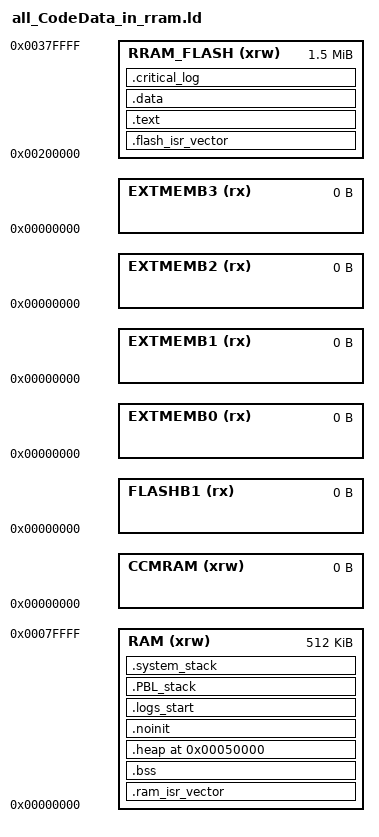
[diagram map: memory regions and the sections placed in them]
/*
 * This file is part of the µOS++ distribution.
 *   (https://github.com/micro-os-plus)
 * Copyright (c) 2014 Liviu Ionescu.
 *
 * Permission is hereby granted, free of charge, to any person
 * obtaining a copy of this software and associated documentation
 * files (the "Software"), to deal in the Software without
 * restriction, including without limitation the rights to use,
 * copy, modify, merge, publish, distribute, sublicense, and/or
 * sell copies of the Software, and to permit persons to whom
 * the Software is furnished to do so, subject to the following
 * conditions:
 *
 * The above copyright notice and this permission notice shall be
 * included in all copies or substantial portions of the Software.
 *
 * THE SOFTWARE IS PROVIDED "AS IS", WITHOUT WARRANTY OF ANY KIND,
 * EXPRESS OR IMPLIED, INCLUDING BUT NOT LIMITED TO THE WARRANTIES
 * OF MERCHANTABILITY, FITNESS FOR A PARTICULAR PURPOSE AND
 * NONINFRINGEMENT. IN NO EVENT SHALL THE AUTHORS OR COPYRIGHT
 * HOLDERS BE LIABLE FOR ANY CLAIM, DAMAGES OR OTHER LIABILITY,
 * WHETHER IN AN ACTION OF CONTRACT, TORT OR OTHERWISE, ARISING
 * FROM, OUT OF OR IN CONNECTION WITH THE SOFTWARE OR THE USE OR
 * OTHER DEALINGS IN THE SOFTWARE.
 */

/* Default linker script for Cortex-M  */
 
 /**************Linker Script for Performance Testing**********************************
 * All code and data will be executing from RRAM.
 * RAM ISR, BSS, stack and heap are in RAM.
 *************************************************************************************/
 
 
 MEMORY
{
  RRAM_FLASH (xrw) : ORIGIN = 0x00200000, LENGTH = 0x00180000
  RAM (xrw) : ORIGIN = 0x00000000, LENGTH = 0x00080000

  /*
   * Optional sections; define the origin and length to match
   * the the specific requirements of your hardware. The zero
   * length prevents inadvertent allocation.
   */
  CCMRAM (xrw) : ORIGIN = 0x00000000, LENGTH = 0
  FLASHB1 (rx) : ORIGIN = 0x00000000, LENGTH = 0
  EXTMEMB0 (rx) : ORIGIN = 0x00000000, LENGTH = 0
  EXTMEMB1 (rx) : ORIGIN = 0x00000000, LENGTH = 0
  EXTMEMB2 (rx) : ORIGIN = 0x00000000, LENGTH = 0
  EXTMEMB3 (rx) : ORIGIN = 0x00000000, LENGTH = 0
}
 
 _ln_PBL_stack__ = ORIGIN(RAM) + LENGTH(RAM);
 _ln_PBL_stack_size__ = 0x200 ;
 _ln_PBL_stack_limit__ = _ln_PBL_stack__ - _ln_PBL_stack_size__ ; 

/*
 * The '__stack' definition is required by crt0, do not remove it.
 */
__stack = _ln_PBL_stack_limit__ ;

_estack = __stack; 	/* End of System Stack */

/*
 * Default stack sizes.
 * These are used by the startup in order to allocate stacks 
 * for the different modes.
 */

__Main_Stack_Size = 10240 ;		/* 10 KB system stack */

PROVIDE ( _Main_Stack_Size = __Main_Stack_Size ) ;

__Main_Stack_Limit = __stack  - __Main_Stack_Size ;

/* "PROVIDE" allows to easily override these values from an 
 * object file or the command line. */
PROVIDE ( _Main_Stack_Limit = __Main_Stack_Limit ) ;

/*
 * Default heap definitions.
 * The heap start immediately after the last statically allocated 
 * .sbss/.noinit section, and extends up to the main stack limit.
 */
PROVIDE ( _Heap_Begin = _end_noinit ) ;
PROVIDE ( _Heap_Limit = __stack - __Main_Stack_Size ) ;
/* 
 * The entry point is informative, for debuggers and simulators,
 * since the Cortex-M vector points to it anyway.
 */
ENTRY(_start)


/* Sections Definitions */

SECTIONS
{
    /*
     * For Cortex-M devices, the beginning of the startup code is stored in
     * the .flash_isr_vector section, which goes to RRAM(FLASH). 
     */
    .flash_isr_vector : ALIGN(4)
    {
        FILL(0xFF)
        
        _ln_RF_flash_isr_vector_start__ = . ;
        __vectors_start = ABSOLUTE(.) ;
        
        KEEP(*(.flash_isr_vector))     	/* Interrupt vectors */
        
		KEEP(*(.cfmconfig))			/*Freescale configuration words */   	     
    } >RRAM_FLASH
    
 	_ln_start_add_ram_isr_vector = _ln_RF_flash_isr_vector_start__ + SIZEOF(.flash_isr_vector) ;
    
    .ram_isr_vector : ALIGN(4)         /* which goes to RAM*/
    {
    	FILL(0xFF)
    	_ln_addr_map_to_ram = ABSOLUTE(.); /*starting address of ram*/
    	KEEP(*(.ram_isr_vector))
    	. += 56;                        /* 64 bytes allocated for ram vector*/
    	. = ALIGN(4) ; 
    	
    } >RAM
    
    _ln_ram_isr_vector_size = SIZEOF(.ram_isr_vector);
    
	/*
     * The program code is stored in the .text section, 
     * which goes to FLASH.
     */
    .text : ALIGN(4)
    {
        *(.after_vectors .after_vectors.*)	/* Startup code and ISR */
        *(.text .text.*)			/* all remaining code */

 		/* read-only data (constants) */
        *(.rodata .rodata.* .constdata .constdata.*) 		

        *(vtable)					/* C++ virtual tables */

		KEEP(*(.eh_frame*))

		/*
		 * Stub sections generated by the linker, to glue together 
		 * ARM and Thumb code. .glue_7 is used for ARM code calling 
		 * Thumb code, and .glue_7t is used for Thumb code calling 
		 * ARM code. Apparently always generated by the linker, for some
		 * architectures, so better leave them here.
		 */
        *(.glue_7)
        *(.glue_7t)

    } >RRAM_FLASH

    /*
     * The initialised data section.
     *
     * The program executes knowing that the data is in the RAM
     * but the loader puts the initial values in the FLASH (inidata).
     * It is one task of the startup to copy the initial values from 
     * FLASH to RAM.
     */
    .data : ALIGN(4)
    {
    	FILL(0xFF)
        /* This is used by the startup code to initialise the .data section */
        
        __data_start__ = . ;
		*(.data_begin .data_begin.*)

		*(.data .data.*)
		
		*(.data_end .data_end.*)
	    . = ALIGN(4);

	    /* This is used by the startup code to initialise the .data section */
        
        __data_end__ = . ;

    } >RRAM_FLASH 
    
    .critical_log : ALIGN(4)
	{
		FILL(0x0) 
		_logs_crit = ABSOLUTE(.);     
	} >RRAM_FLASH

    /* The primary uninitialised data section. */
    .bss (NOLOAD) : ALIGN(4)
    {
        _ln_bss_start__ = .;     	/* standard newlib definition */
        
        *(.bss_begin .bss_begin.*)

        *(.bss .bss.*)
        *(COMMON)
        
        *(.bss_end .bss_end.*)
	    . = ALIGN(4);
        _ln_bss_end__ = .;        /* standard newlib definition */
        
    } >RAM

	.heap 0x50000 : ALIGN(4)
	{
		_ln_heap_start__ = ABSOLUTE(.) ;
		*(.heap) 
		. = ALIGN(4) ;
		_ln_heap_end__ = ABSOLUTE(.) ;
	} >RAM
	
    .noinit (NOLOAD) : ALIGN(4)
    {
        _noinit = .;
        
        *(.noinit .noinit.*) 
        
         . = ALIGN(4) ;
        _end_noinit = .;   
    } > RAM
    
/* ----------------------------------------- Logs Section ------------------------------------- */	

/* The VMA and the memory reservation for log buffers is defined here for all the log types/levels. 
The VMAs obtained from the linker script are used in the logger */
	.logs_start : ALIGN (4)
	{
		FILL(0x0) 
		_logs_info = ABSOLUTE(.);	/* Info Logs */
		. += 4096;
		FILL(0x0) 
		_logs_warn = ABSOLUTE(.);	/* Warning Logs */
		. += 4096;
		FILL(0x0) 
		_logs_err = ABSOLUTE(.);	/* Error Logs */
		. += 4096;
	} > RAM
    

    /* Mandatory to be word aligned, _sbrk assumes this */
    PROVIDE ( end = _end_noinit ); /* was _ebss */
    PROVIDE ( _end = _end_noinit );
    PROVIDE ( __end = _end_noinit );
    PROVIDE ( __end__ = _end_noinit );
    
    .PBL_stack _ln_PBL_stack_limit__ (NOLOAD) : ALIGN(4)
    {
    	. += _ln_PBL_stack_size__ ; 
    } >RAM
    
    .system_stack __Main_Stack_Limit (NOLOAD) : ALIGN(4)
    {
    	. += __Main_Stack_Size ;
    } >RAM
  

    /* After that there are only debugging sections. */
    
    /* This can remove the debugging information from the standard libraries */    
  
  
    /* Stabs debugging sections.  */
    .stab          0 : { *(.stab) }
    .stabstr       0 : { *(.stabstr) }
    .stab.excl     0 : { *(.stab.excl) }
    .stab.exclstr  0 : { *(.stab.exclstr) }
    .stab.index    0 : { *(.stab.index) }
    .stab.indexstr 0 : { *(.stab.indexstr) }
    .comment       0 : { *(.comment) }
    /*
     * DWARF debug sections.
     * Symbols in the DWARF debugging sections are relative to the beginning
     * of the section so we begin them at 0.  
     */
    /* DWARF 1 */
    .debug          0 : { *(.debug) }
    .line           0 : { *(.line) }
    /* GNU DWARF 1 extensions */
    .debug_srcinfo  0 : { *(.debug_srcinfo) }
    .debug_sfnames  0 : { *(.debug_sfnames) }
    /* DWARF 1.1 and DWARF 2 */
    .debug_aranges  0 : { *(.debug_aranges) }
    .debug_pubnames 0 : { *(.debug_pubnames) }
    /* DWARF 2 */
    .debug_info     0 : { *(.debug_info .gnu.linkonce.wi.*) }
    .debug_abbrev   0 : { *(.debug_abbrev) }
    .debug_line     0 : { *(.debug_line) }
    .debug_frame    0 : { *(.debug_frame) }
    .debug_str      0 : { *(.debug_str) }
    .debug_loc      0 : { *(.debug_loc) }
    .debug_macinfo  0 : { *(.debug_macinfo) }
    /* SGI/MIPS DWARF 2 extensions */
    .debug_weaknames 0 : { *(.debug_weaknames) }
    .debug_funcnames 0 : { *(.debug_funcnames) }
    .debug_typenames 0 : { *(.debug_typenames) }
    .debug_varnames  0 : { *(.debug_varnames) }    
}
